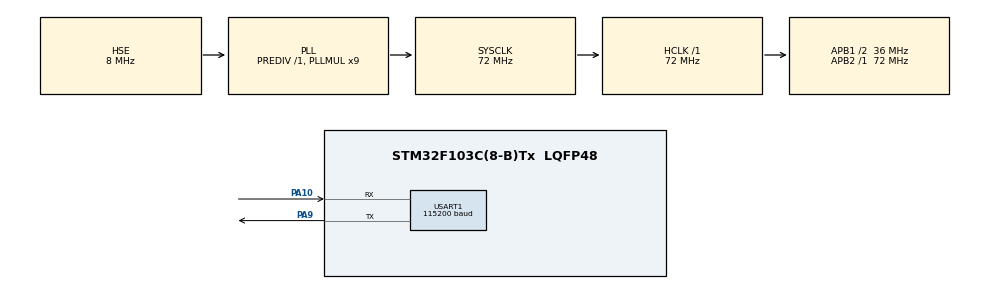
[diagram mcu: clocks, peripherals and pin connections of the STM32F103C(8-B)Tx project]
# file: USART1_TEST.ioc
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Dma.Request0=USART1_RX
Dma.Request1=USART1_TX
Dma.USART1_RX.0.Direction=DMA_PERIPH_TO_MEMORY
Dma.USART1_RX.0.Instance=DMA1_Channel5
Dma.USART1_RX.0.MemDataAlignment=DMA_MDATAALIGN_BYTE
Dma.USART1_RX.0.MemInc=DMA_MINC_ENABLE
Dma.USART1_RX.0.Mode=DMA_NORMAL
Dma.USART1_RX.0.PeriphDataAlignment=DMA_PDATAALIGN_BYTE
Dma.USART1_RX.0.PeriphInc=DMA_PINC_DISABLE
Dma.USART1_RX.0.Priority=DMA_PRIORITY_LOW
Dma.USART1_TX.1.Direction=DMA_MEMORY_TO_PERIPH
Dma.USART1_TX.1.Instance=DMA1_Channel4
Dma.USART1_TX.1.MemDataAlignment=DMA_MDATAALIGN_BYTE
Dma.USART1_TX.1.MemInc=DMA_MINC_ENABLE
Dma.USART1_TX.1.Mode=DMA_NORMAL
Dma.USART1_TX.1.PeriphDataAlignment=DMA_PDATAALIGN_BYTE
Dma.USART1_TX.1.PeriphInc=DMA_PINC_DISABLE
Dma.USART1_TX.1.Priority=DMA_PRIORITY_LOW
Mcu.Family=STM32F1
Mcu.Name=STM32F103C(8-B)Tx
Mcu.Package=LQFP48
NVIC.DMA1_Channel4_IRQn=true\:0\:0\:false\:false\:true\:false\:true\:true
NVIC.DMA1_Channel5_IRQn=true\:0\:0\:false\:false\:true\:false\:true\:true
NVIC.PriorityGroup=NVIC_PRIORITYGROUP_2
NVIC.USART1_IRQn=true\:3\:3\:true\:false\:true\:true\:true\:true
PA10.Mode=Asynchronous
PA10.Signal=USART1_RX
PA13.Mode=Serial_Wire
PA13.Signal=SYS_JTMS-SWDIO
PA14.Mode=Serial_Wire
PA14.Signal=SYS_JTCK-SWCLK
PA9.Mode=Asynchronous
PA9.Signal=USART1_TX
PD0-OSC_IN.Mode=HSE-External-Oscillator
PD0-OSC_IN.Signal=RCC_OSC_IN
PD1-OSC_OUT.Mode=HSE-External-Oscillator
PD1-OSC_OUT.Signal=RCC_OSC_OUT
ProjectManager.HeapSize=0x200
ProjectManager.StackSize=0x400
ProjectManager.TargetToolchain=CMake
RCC.AHBFreq_Value=72000000
RCC.APB1CLKDivider=RCC_HCLK_DIV2
RCC.APB1Freq_Value=36000000
RCC.APB1TimFreq_Value=72000000
RCC.APB2Freq_Value=72000000
RCC.APB2TimFreq_Value=72000000
RCC.HCLKFreq_Value=72000000
RCC.PLLMUL=RCC_PLL_MUL9
RCC.PLLSourceVirtual=RCC_PLLSOURCE_HSE
RCC.SYSCLKFreq_VALUE=72000000
RCC.SYSCLKSource=RCC_SYSCLKSOURCE_PLLCLK
RCC.USBFreq_Value=72000000
USART1.BaudRate=115200
USART1.VirtualMode=VM_ASYNC
USART1.WordLength=WORDLENGTH_8B
board=custom

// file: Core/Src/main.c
/* USER CODE BEGIN Header */
/**
  ******************************************************************************
  * @file           : main.c
  * @brief          : Main program body
  ******************************************************************************
  * @attention
  *
  * Copyright (c) 2026 STMicroelectronics.
  * All rights reserved.
  *
  * This software is licensed under terms that can be found in the LICENSE file
  * in the root directory of this software component.
  * If no LICENSE file comes with this software, it is provided AS-IS.
  *
  ******************************************************************************
  */
/* USER CODE END Header */
#include "main.h"

/* USER CODE BEGIN Includes */
#include <stdio.h>
#include <math.h>
/* USER CODE END Includes */

/* USER CODE BEGIN PD */
#define USART1_RX_BUFFER_SIZE 50
/* USER CODE END PD */

UART_HandleTypeDef huart1;
DMA_HandleTypeDef hdma_usart1_rx;
DMA_HandleTypeDef hdma_usart1_tx;

/* USER CODE BEGIN PV */
static uint8_t Usart1_Rxbuffer[USART1_RX_BUFFER_SIZE]={0};
/* USER CODE END PV */

void SystemClock_Config(void);
static void MX_GPIO_Init(void);
static void MX_DMA_Init(void);
static void MX_USART1_UART_Init(void);

int main(void)
{

  /* MCU Configuration--------------------------------------------------------*/

  /* Reset of all peripherals, Initializes the Flash interface and the Systick. */
  HAL_Init();

  /* Configure the system clock */
  SystemClock_Config();

  /* Initialize all configured peripherals */
  MX_GPIO_Init();
  MX_DMA_Init();
  MX_USART1_UART_Init();
  /* USER CODE BEGIN 2 */

  HAL_UARTEx_ReceiveToIdle_DMA(&huart1, Usart1_Rxbuffer, USART1_RX_BUFFER_SIZE);
  __HAL_DMA_DISABLE_IT(&hdma_usart1_rx, DMA_IT_HT); // 禁用接收通道的半传输中断
  __HAL_DMA_DISABLE_IT(&hdma_usart1_tx, DMA_IT_HT); // 禁用发送通道的半传输中断
  // HAL_UART_Receive_IT(&huart1, Usart1_Rxbuffer,1);
  // HAL_UART_Receive_DMA(&huart1, Usart1_Rxbuffer, 1);

  /* USER CODE END 2 */

  /* Infinite loop */
  while (1)
  {

  }
}

void SystemClock_Config(void)
{
  RCC_OscInitTypeDef RCC_OscInitStruct = {0};
  RCC_ClkInitTypeDef RCC_ClkInitStruct = {0};

  /** Initializes the RCC Oscillators according to the specified parameters
  * in the RCC_OscInitTypeDef structure.
  */
  RCC_OscInitStruct.OscillatorType = RCC_OSCILLATORTYPE_HSE;
  RCC_OscInitStruct.HSEState = RCC_HSE_ON;
  RCC_OscInitStruct.HSEPredivValue = RCC_HSE_PREDIV_DIV1;
  RCC_OscInitStruct.HSIState = RCC_HSI_ON;
  RCC_OscInitStruct.PLL.PLLState = RCC_PLL_ON;
  RCC_OscInitStruct.PLL.PLLSource = RCC_PLLSOURCE_HSE;
  RCC_OscInitStruct.PLL.PLLMUL = RCC_PLL_MUL9;
  if (HAL_RCC_OscConfig(&RCC_OscInitStruct) != HAL_OK)
  {
    Error_Handler();
  }

  /** Initializes the CPU, AHB and APB buses clocks
  */
  RCC_ClkInitStruct.ClockType = RCC_CLOCKTYPE_HCLK|RCC_CLOCKTYPE_SYSCLK
                              |RCC_CLOCKTYPE_PCLK1|RCC_CLOCKTYPE_PCLK2;
  RCC_ClkInitStruct.SYSCLKSource = RCC_SYSCLKSOURCE_PLLCLK;
  RCC_ClkInitStruct.AHBCLKDivider = RCC_SYSCLK_DIV1;
  RCC_ClkInitStruct.APB1CLKDivider = RCC_HCLK_DIV2;
  RCC_ClkInitStruct.APB2CLKDivider = RCC_HCLK_DIV1;

  if (HAL_RCC_ClockConfig(&RCC_ClkInitStruct, FLASH_LATENCY_2) != HAL_OK)
  {
    Error_Handler();
  }
}

static void MX_USART1_UART_Init(void)
{

  huart1.Instance = USART1;
  huart1.Init.BaudRate = 115200;
  huart1.Init.WordLength = UART_WORDLENGTH_8B;
  huart1.Init.StopBits = UART_STOPBITS_1;
  huart1.Init.Parity = UART_PARITY_NONE;
  huart1.Init.Mode = UART_MODE_TX_RX;
  huart1.Init.HwFlowCtl = UART_HWCONTROL_NONE;
  huart1.Init.OverSampling = UART_OVERSAMPLING_16;
  if (HAL_UART_Init(&huart1) != HAL_OK)
  {
    Error_Handler();
  }

}

static void MX_DMA_Init(void)
{

  /* DMA controller clock enable */
  __HAL_RCC_DMA1_CLK_ENABLE();

  /* DMA interrupt init */
  /* DMA1_Channel4_IRQn interrupt configuration */
  HAL_NVIC_SetPriority(DMA1_Channel4_IRQn, 0, 0);
  HAL_NVIC_EnableIRQ(DMA1_Channel4_IRQn);
  /* DMA1_Channel5_IRQn interrupt configuration */
  HAL_NVIC_SetPriority(DMA1_Channel5_IRQn, 0, 0);
  HAL_NVIC_EnableIRQ(DMA1_Channel5_IRQn);

}

static void MX_GPIO_Init(void)
{
  GPIO_InitTypeDef GPIO_InitStruct = {0};

  /* GPIO Ports Clock Enable */
  __HAL_RCC_GPIOC_CLK_ENABLE();
  __HAL_RCC_GPIOD_CLK_ENABLE();
  __HAL_RCC_GPIOA_CLK_ENABLE();
  __HAL_RCC_GPIOB_CLK_ENABLE();

  /*Configure GPIO pins : PC13 PC14 PC15 */
  GPIO_InitStruct.Pin = GPIO_PIN_13|GPIO_PIN_14|GPIO_PIN_15;
  GPIO_InitStruct.Mode = GPIO_MODE_ANALOG;
  HAL_GPIO_Init(GPIOC, &GPIO_InitStruct);

  /*Configure GPIO pins : PA0 PA1 PA2 PA3
                           PA4 PA5 PA6 PA7
                           PA8 PA11 PA12 PA15 */
  GPIO_InitStruct.Pin = GPIO_PIN_0|GPIO_PIN_1|GPIO_PIN_2|GPIO_PIN_3
                          |GPIO_PIN_4|GPIO_PIN_5|GPIO_PIN_6|GPIO_PIN_7
                          |GPIO_PIN_8|GPIO_PIN_11|GPIO_PIN_12|GPIO_PIN_15;
  GPIO_InitStruct.Mode = GPIO_MODE_ANALOG;
  HAL_GPIO_Init(GPIOA, &GPIO_InitStruct);

  /*Configure GPIO pins : PB0 PB1 PB2 PB10
                           PB11 PB12 PB13 PB14
                           PB15 PB3 PB4 PB5
                           PB6 PB7 PB8 PB9 */
  GPIO_InitStruct.Pin = GPIO_PIN_0|GPIO_PIN_1|GPIO_PIN_2|GPIO_PIN_10
                          |GPIO_PIN_11|GPIO_PIN_12|GPIO_PIN_13|GPIO_PIN_14
                          |GPIO_PIN_15|GPIO_PIN_3|GPIO_PIN_4|GPIO_PIN_5
                          |GPIO_PIN_6|GPIO_PIN_7|GPIO_PIN_8|GPIO_PIN_9;
  GPIO_InitStruct.Mode = GPIO_MODE_ANALOG;
  HAL_GPIO_Init(GPIOB, &GPIO_InitStruct);

}

/* USER CODE BEGIN 4 */

void HAL_UARTEx_RxEventCallback(UART_HandleTypeDef *huart, uint16_t Size)
{
  if(huart->Instance == USART1)
  {
    HAL_UART_Transmit_DMA(&huart1, Usart1_Rxbuffer, Size);
    HAL_UARTEx_ReceiveToIdle_DMA(&huart1, Usart1_Rxbuffer, USART1_RX_BUFFER_SIZE);
    __HAL_DMA_DISABLE_IT(&hdma_usart1_rx, DMA_IT_HT); // 禁用接收通道的半传输中断
  __HAL_DMA_DISABLE_IT(&hdma_usart1_tx, DMA_IT_HT); // 禁用发送通道的半传输中断
  }
}

// void HAL_UART_RxCpltCallback(UART_HandleTypeDef *huart)
// {
//   if(huart->Instance == USART1)
//   {
//     HAL_UART_Transmit_DMA(&huart1, Usart1_Rxbuffer, 1);
//     HAL_UART_Receive_DMA(&huart1, Usart1_Rxbuffer, 1);
//     __HAL_DMA_DISABLE_IT(&hdma_usart1_rx, DMA_IT_HT);
//   }
// }

// 重写_write函数，用于printf重定向到USART1
int _write(int file, char *ptr, int len)
{
  // 只处理标准输出(stdout, 文件描述符1)和标准错误(stderr, 文件描述符2)
  if (file != 1 && file != 2) {
    return -1;
  }

    // 关键：等待上一次 DMA 传输完成（gState 变为 READY）
  while (huart1.gState != HAL_UART_STATE_READY) {
    // 可选：添加超时判断，避免死等（比如电机控制场景，超时返回错误）
    static uint32_t timeout = 0;
    if (++timeout > 100000) { // 约 1ms（72MHz 主频）
      timeout = 0;
      return -1; // 超时失败
    }
  }

  // 使用DMA式UART传输发送数据
  if (HAL_UART_Transmit_DMA(&huart1, (uint8_t*)ptr, len) != HAL_OK) {
    return -1; // 传输错误，返回-1表示失败
  }

  return len; // 返回成功发送的字节数
}

/* USER CODE END 4 */

void Error_Handler(void)
{
  __disable_irq();
  while (1)
  {
  }
}
